# WDT register map
Vendor: Texas Instruments
Peripheral module from a debugger description file (folder am437x).
Registers are 32-bit, access per field, no defined reset value unless marked. A register's access mark holds for its fields unless they carry their own. Offsets are as the file gives them; lines under a group give offsets from that group; [hi:lo] are bit positions; {n}, {i} and the like mark numbered series; 'fields as' and 'values as' point back to an identical list; <NAME> marks a mode.

## WDT
0x00 WDT_WIDR ro — Watchdog Identification Register
  [31:0] REVISION — IP Revision
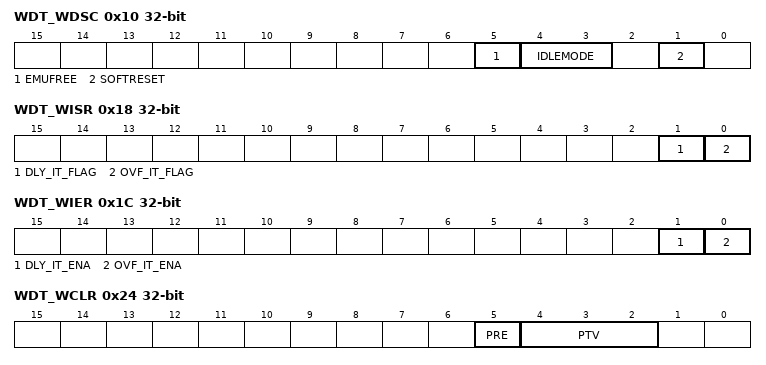
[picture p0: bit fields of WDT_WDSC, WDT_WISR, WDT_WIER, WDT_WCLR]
0x10 WDT_WDSC — The Watchdog System Control Register controls the various parameters of the L4 interface.
  [5] EMUFREE rw — Sensitivity to emulation (debug) suspend event from Debug Subsystem.
    1=en_2_0x1 (Timer counter free-running. Debug suspend event is ignored.); 0=en_1_0x0 (Timer counter frozen during debug suspend event.)
  [4:3] IDLEMODE rw — Configuration of the local target state management mode.By definition, target can handle read/write transaction as long as it is out of IDLE state.
    3=en_4_0x3 (Smart-idle wakeup-capable mode: local target's idle state eventually follows (acknowledges) the system's idle requests, depending on the IP module's internal requirements. IP module may generate (IRQ- or DMA-request-related) wakeup events when in idle state.); 2=en_3_0x2 (Smart-idle mode: local target's idle state eventually follows (acknowledges) the system's idle requests, depending on the IP module's internal requirements. IP module shall not generate (IRQ- or DMA-request-related) wakeup events.); 1=en_2_0x1 (No-idle mode: local target never enters idle state.Backup mode, for debug only.); 0=en_1_0x0 (Force-idle mode: local target's idle state follows (acknowledges) the system's idle requests unconditionally, i.e. regardless of the IP module's internal requirements. Backup mode, for debug only.)
  [1] SOFTRESET rw — Software reset. [[br]](Optional)
    1=en_4_0x1 (Reset (software or other) ongoing); 1=en_3_0x1 (Initiate software reset); 0=en_2_0x0 (No action); 0=en_1_0x0 (Reset done, no pending action)
0x14 WDT_WDST ro — The Watchdog Status Register provides status information about the module.
  [0] RESETDONE — Internal module reset monitoring
    1=en_2_0x1 (Reset completed); 0=en_1_0x0 (Internal module reset is ongoing.)
0x18 WDT_WISR — The Watchdog Interrupt Status Register shows which interrupt events are pending inside the module.
  [1] DLY_IT_FLAG rw — Pending delay interrupt status.
    1=en_4_0x1 (Status bit cleared); 1=en_3_0x1 (Delay interrupt pending); 0=en_2_0x0 (No delay interrupt pending); 0=en_1_0x0 (Status unchanged)
  [0] OVF_IT_FLAG rw — Pending overflow interrupt status.
    1=en_4_0x1 (Status bit cleared); 1=en_3_0x1 (Overflow interrupt pending); 0=en_2_0x0 (No overflow interrupt pending); 0=en_1_0x0 (Status unchanged)
0x1C WDT_WIER — The Watchdog Interrupt Enable Register controls (enable/disable) the interrupt events.
  [1] DLY_IT_ENA rw — Delay interrupt enable/disable
    1=en_2_0x1 (Enable delay interrupt.); 0=en_1_0x0 (Disable delay interrupt.)
  [0] OVF_IT_ENA rw — Overflow interrupt enable/disable
    1=en_2_0x1 (Enable overflow interrupt.); 0=en_1_0x0 (Disable overflow interrupt.)
0x24 WDT_WCLR — The Watchdog Control Register controls the prescaler stage of the counter.
  [5] PRE rw — Prescaler enable/disable configuration
    1=en_2_0x1 (Prescaler enabled); 0=en_1_0x0 (Prescaler disabled)
  [4:2] PTV rw — Prescaler value. [[br]]The timer counter is prescaled with the value: 2**PTV. [[br]]Example: PTV = 3 then counter increases value if started after 8 functional clock periods. [[br]]On reset, it is loaded from PI_PTV_RESET_VALUE input port.
0x28 WDT_WCRR rw — The Watchdog Counter Register holds the value of the internal counter.
  [31:0] TIMER_CTR — Value of the timer counter register
0x2C WDT_WLDR rw — The Watchdog Load Register holds the timer load value.
  [31:0] TIMER_LOAD — Value of the timer load register
0x30 WDT_WTGR rw — Writing a different value than the one already written in the Watchdog Trigger Register does a watchdog counter reload.
  [31:0] TTGR_VALUE — Value of the trigger register
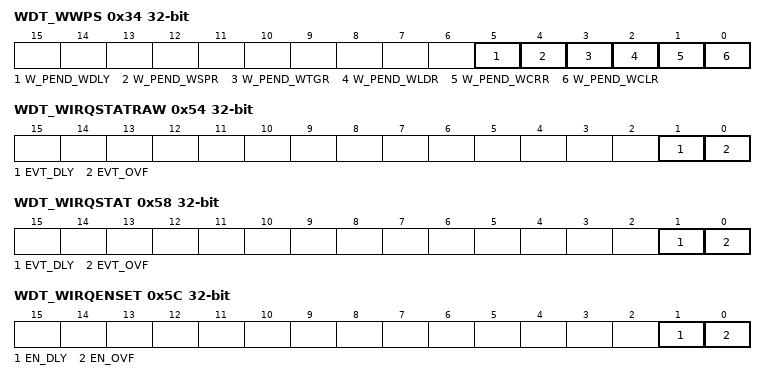
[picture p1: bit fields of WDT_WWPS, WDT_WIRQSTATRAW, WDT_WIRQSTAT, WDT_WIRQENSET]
0x34 WDT_WWPS ro — The Watchdog Write Posting Bits Register contains the write posting bits for all writeable functional registers.
  [all] fields
    1=en_2_0x1 (Register write pending); 0=en_1_0x0 (No register write pending)
  [5] W_PEND_WDLY — Write pending for register WDLY
  [4] W_PEND_WSPR — Write pending for register WSPR
  [3] W_PEND_WTGR — Write pending for register WTGR
  [2] W_PEND_WLDR — Write pending for register WLDR
  [1] W_PEND_WCRR — Write pending for register WCRR
  [0] W_PEND_WCLR — Write pending for register WCLR
0x44 WDT_WDLY rw — The Watchdog Delay Configuration Register holds the delay value that controls the internal pre-overflow event detection.
  [31:0] WDLY_VALUE — Value of the delay register
0x48 WDT_WSPR rw — The Watchdog Start/Stop Register holds the start-stop value that controls the internal start-stop FSM.
  [31:0] WSPR_VALUE — Value of the start-stop register
0x54 WDT_WIRQSTATRAW — In the Watchdog Raw Interrupt Status Register, IRQ unmasked status, status set per-event raw interrupt status vector, line 0. Raw status is set even if event is not enabled. Write 1 to set the (raw) status, mostly for debug.
  [1] EVT_DLY rw — Settable raw status for delay event
    1=en_4_0x1 (Set event (debug)); 1=en_3_0x1 (Event pending); 0=en_2_0x0 (No event pending); 0=en_1_0x0 (No action)
  [0] EVT_OVF rw — Settable raw status for overflow event
    values as EVT_DLY
0x58 WDT_WIRQSTAT — In the Watchdog Interrupt Status Register, IRQ masked status, status clear per-event enabled interrupt status vector, line 0. Enabled status is not set unless event is enabled. Write 1 to clear the status after interrupt has been serviced (raw status gets cleared, that is, even if not enabled).
  [1] EVT_DLY rw — Clearable, enabled status for delay event
    1=en_4_0x1 (Clear (raw) event); 1=en_3_0x1 (Event pending); 0=en_2_0x0 (No action); 0=en_1_0x0 (No (enabled) event pending)
  [0] EVT_OVF rw — Clearable, enabled status for overflow event
    values as EVT_DLY
0x5C WDT_WIRQENSET — In the Watchdog Interrupt Enable Set Register, IRQ enable set per-event interrupt enable bit vector, line 0. Write 1 to set (enable interrupt). Readout equal to corresponding _CLR register.
  [1] EN_DLY rw — Enable for delay event
    1=en_4_0x1 (Interrupt enabled); 1=en_3_0x1 (Enable interrupt); 0=en_2_0x0 (Interrupt disabled (masked)); 0=en_1_0x0 (No action)
  [0] EN_OVF rw — Enable for overflow event
    values as EN_DLY
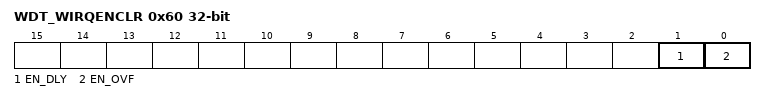
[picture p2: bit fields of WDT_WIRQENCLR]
0x60 WDT_WIRQENCLR — In the Watchdog Interrupt Enable Clear Register, IRQ enable clear per-event interrupt enable bit vector, line 0. Write 1 to clear (disable interrupt). Readout equal to corresponding _SET register.
  [1] EN_DLY rw — Enable for delay event
    1=en_4_0x1 (Disable interrupt); 1=en_3_0x1 (Interrupt enabled); 0=en_2_0x0 (Interrupt disabled (masked)); 0=en_1_0x0 (No action)
  [0] EN_OVF rw — Enable for overflow event
    values as EN_DLY
